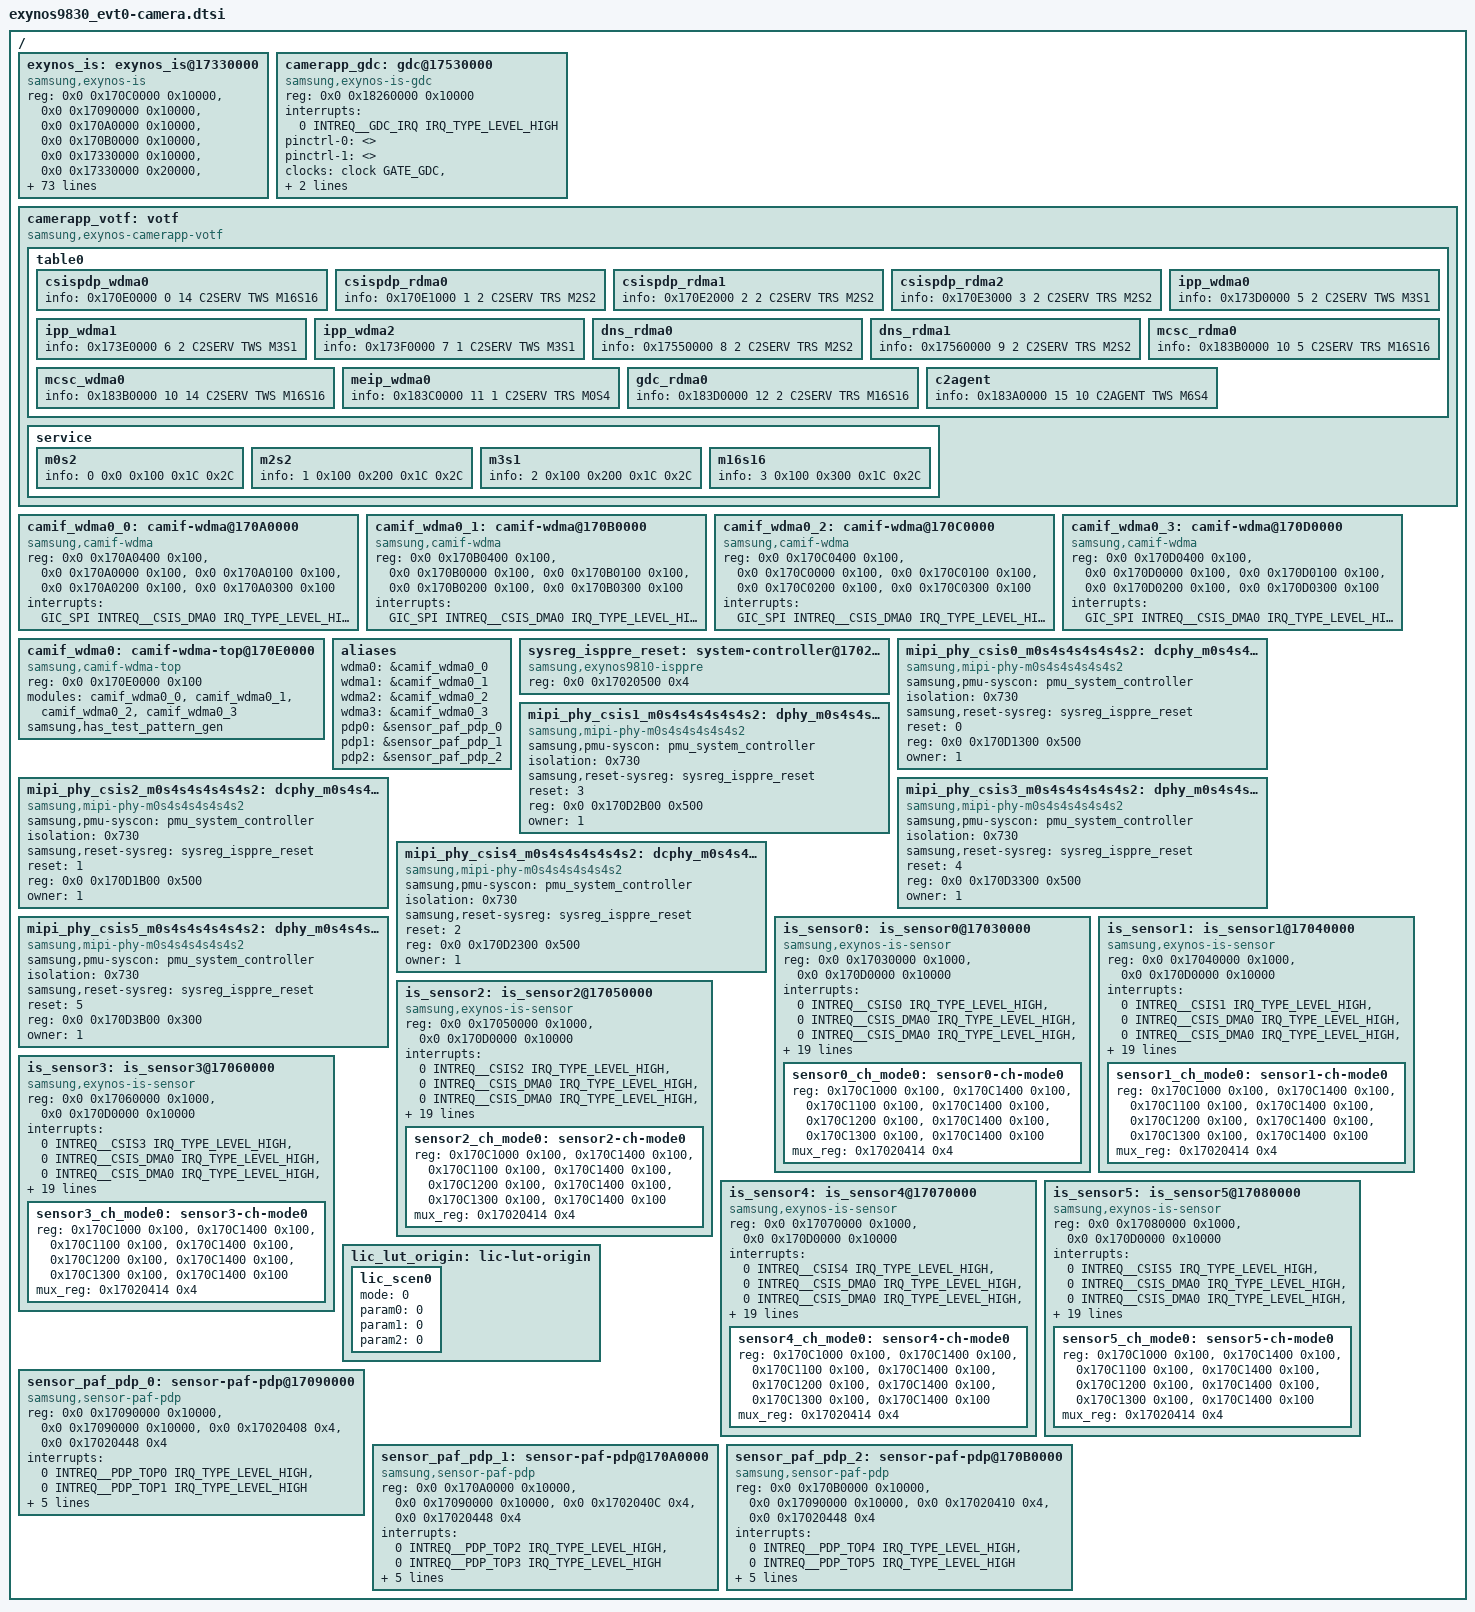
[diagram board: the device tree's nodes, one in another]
/*
 * SAMSUNG EXYNOS9830 SoC camera device tree source
 *
 * Copyright (c) 2019 Samsung Electronics Co., Ltd.
 *		http://www.samsung.com
 *
 * SAMSUNG EXYNOS9830 SoC camera device nodes are listed in this file.
 * EXYNOS9830 based board files can include this file and provide
 * values for board specfic bindings.
 *
 * This program is free software; you can redistribute it and/or modify
 * it under the terms of the GNU General Public License version 2 as
 * published by the Free Software Foundation.
 */

#include <dt-bindings/clock/exynos9830_evt0.h>
#include <dt-bindings/interrupt-controller/arm-gic.h>
#include <dt-bindings/interrupt-controller/exynos9830.h>
#include <dt-bindings/sysmmu/sysmmu.h>
#include <dt-bindings/camera/exynos_is_dt.h>
#include <dt-bindings/camera/votf.h>
#include "exynos9830-pinctrl.dtsi"

/ {
	exynos_is: exynos_is@17330000 {
		compatible = "samsung,exynos-is";
		reg = <0x0 0x170C0000 0x10000>, /* CSIS DMA  */
			<0x0 0x17090000 0x10000>, /* PDP CORE0 */
			<0x0 0x170A0000 0x10000>, /* PDP CORE1 */
			<0x0 0x170B0000 0x10000>, /* PDP CORE2 */
			<0x0 0x17330000 0x10000>, /* IPP0 */
			<0x0 0x17330000 0x20000>, /* IPP1 */
			<0x0 0x17330000 0x30000>, /* IPP2 */
			<0x0 0x170C0000 0x10000>, /* ZSL/STRIP DMA  */
			<0x0 0x18250000 0x10000>, /* MEIP */
			<0x0 0x17430000 0x10000>, /* ITP0 */
			<0x0 0x17740000 0x10000>, /* TNR */
			<0x0 0x17530000 0x10000>, /* DNS0 */
			<0x0 0x18240000 0x10000>, /* MCSC */
			<0x0 0x18230000 0x10000>, /* ITSC only for EVT0 */
			<0x0 0x17440000 0x10000>, /* ITP1 only for EVT0 */
			<0x0 0x17540000 0x10000>; /* DNS1 only for EVT0 */
		interrupts = <0 INTREQ__IPP_CH0_0 IRQ_TYPE_LEVEL_HIGH>,	/* IPP0_0 */
			<0 INTREQ__IPP_CH0_1 IRQ_TYPE_LEVEL_HIGH>,			/* IPP0_1 */
			<0 INTREQ__MEIP_0 IRQ_TYPE_LEVEL_HIGH>,				/* MEIP_0 */
			<0 INTREQ__ZSL_DMA0 IRQ_TYPE_LEVEL_HIGH>,				/* ZSL_DMA_0 */
			<0 INTREQ__STRP_DMA0 IRQ_TYPE_LEVEL_HIGH>,			/* STRIP_DMA_0 */
			<0 INTREQ__IPP_CH1_0 IRQ_TYPE_LEVEL_HIGH>,			/* IPP1_0 */
			<0 INTREQ__IPP_CH1_1 IRQ_TYPE_LEVEL_HIGH>,			/* IPP1_1 */
			<0 INTREQ__MEIP_1 IRQ_TYPE_LEVEL_HIGH>,				/* MEIP_1 */
			<0 INTREQ__ZSL_DMA1 IRQ_TYPE_LEVEL_HIGH>,				/* ZSL_DMA_1 */
			<0 INTREQ__STRP_DMA1 IRQ_TYPE_LEVEL_HIGH>,			/* STRIP_DMA_1 */
			<0 INTREQ__IPP_CH2_0 IRQ_TYPE_LEVEL_HIGH>,			/* IPP2_0 */
			<0 INTREQ__IPP_CH2_1 IRQ_TYPE_LEVEL_HIGH>,			/* IPP2_1 */
			<0 INTREQ__ZSL_DMA2 IRQ_TYPE_LEVEL_HIGH>,				/* ZSL_DMA_2 */
			<0 INTREQ__STRP_DMA2 IRQ_TYPE_LEVEL_HIGH>,			/* STRIP_DMA_2 */
			<0 INTREQ__DNS0_0 IRQ_TYPE_LEVEL_HIGH>,				/* ITP0_0 */
			<0 INTREQ__DNS0_1 IRQ_TYPE_LEVEL_HIGH>,				/* ITP0_1 */
			<0 INTREQ__TNR IRQ_TYPE_LEVEL_HIGH>,					/* TNR */
			<0 INTREQ__MCSC_OTF0 IRQ_TYPE_LEVEL_HIGH>,			/* MC_SC_0 */
			<0 INTREQ__MCSC_OTF1 IRQ_TYPE_LEVEL_HIGH>,			/* MC_SC_1 */
			<0 INTREQ__DNS1_0 IRQ_TYPE_LEVEL_HIGH>,				/* ITP1_0 */
			<0 INTREQ__DNS1_1 IRQ_TYPE_LEVEL_HIGH>,				/* ITP1_1 */
			<0 INTREQ__ITSC_OTF0 IRQ_TYPE_LEVEL_HIGH>,			/* ITSC_0 */
			<0 INTREQ__ITSC_OTF1 IRQ_TYPE_LEVEL_HIGH>;			/* ITSC_1 */
		pinctrl-names = "default","release";
		pinctrl-0 = <>;
		pinctrl-1 = <>;
		clocks = <&clock UMUX_CLKCMU_IPP_BUS>,
			<&clock GATE_SIPU_IPP>,

			<&clock UMUX_CLKCMU_TNR_BUS>,
			<&clock DOUT_CLK_TNR_BUSP>,
			<&clock GATE_TNR>,

			<&clock UMUX_CLKCMU_DNS_BUS>,
			<&clock GATE_DNS>,

			<&clock UMUX_CLKCMU_ITP_BUS>,
			<&clock GATE_ITP>,

			<&clock UMUX_CLKCMU_MCSC_BUS>,
			<&clock UMUX_CLKCMU_MCSC_MEIP>,
			<&clock UMUX_CLKCMU_MCSC_GDC>,
			<&clock GATE_GDC>,
			<&clock GATE_ITSC>,
			<&clock GATE_MCSC>,
			<&clock GATE_MEIP>,

			<&clock CIS_CLK0>,
			<&clock CIS_CLK1>,
			<&clock CIS_CLK2>,
			<&clock CIS_CLK3>,
			<&clock CIS_CLK4>,
			<&clock CIS_CLK5>,

			<&clock GATE_DFTMUX_TOP_CIS_CLK0>,
			<&clock GATE_DFTMUX_TOP_CIS_CLK1>,
			<&clock GATE_DFTMUX_TOP_CIS_CLK2>,
			<&clock GATE_DFTMUX_TOP_CIS_CLK3>,
			<&clock GATE_DFTMUX_TOP_CIS_CLK4>,
			<&clock GATE_DFTMUX_TOP_CIS_CLK5>,

			<&clock UMUX_CLKCMU_CSIS_BUS>,
			<&clock GATE_CSIS_PDP_CSIS0>,
			<&clock GATE_CSIS_PDP_CSIS1>,
			<&clock GATE_CSIS_PDP_CSIS2>,
			<&clock GATE_CSIS_PDP_CSIS3>,
			<&clock GATE_CSIS_PDP_CSIS4>,
			<&clock GATE_CSIS_PDP_CSIS_DMA>,
			<&clock GATE_CSIS_PDP_CSIS5>,
			<&clock GATE_CSIS_PDP_TOP>;
		clock-names = "UMUX_CLKCMU_IPP_BUS",
			"GATE_SIPU_IPP",

			"UMUX_CLKCMU_TNR_BUS",
			"DOUT_CLK_TNR_BUSP",
			"GATE_TNR",

			"UMUX_CLKCMU_DNS_BUS",
			"GATE_DNS",

			"UMUX_CLKCMU_ITP_BUS",
			"GATE_ITP",

			"UMUX_CLKCMU_MCSC_BUS",
			"UMUX_CLKCMU_MCSC_MEIP",
			"UMUX_CLKCMU_MCSC_GDC",
			"GATE_GDC",
			"GATE_ITSC",
			"GATE_MCSC",
			"GATE_MEIP",

			"CIS_CLK0",
			"CIS_CLK1",
			"CIS_CLK2",
			"CIS_CLK3",
			"CIS_CLK4",
			"CIS_CLK5",

			"MUX_CIS_CLK0",
			"MUX_CIS_CLK1",
			"MUX_CIS_CLK2",
			"MUX_CIS_CLK3",
			"MUX_CIS_CLK4",
			"MUX_CIS_CLK5",

			"UMUX_CLKCMU_CSIS_BUS",
			"GATE_CSIS_PDP_CSIS0",
			"GATE_CSIS_PDP_CSIS1",
			"GATE_CSIS_PDP_CSIS2",
			"GATE_CSIS_PDP_CSIS3",
			"GATE_CSIS_PDP_CSIS4",
			"GATE_CSIS_PDP_CSIS_DMA",
			"GATE_CSIS_PDP_CSIS5",
			"GATE_CSIS_PDP_TOP";
		status = "ok";
		iommus = <&sysmmu_csis1>, <&sysmmu_ipp>, <&sysmmu_tnr>, <&sysmmu_dns>, <&sysmmu_mcsc0>, <&sysmmu_mcsc1>;
		#cooling-cells = <2>; /* min followed by max */
		/* ewf-index = <EWF_CMU_BUSC>; */
		list-scen-bts = "camera_default";
		num_of_3aa = <3>;
		num_of_isp = <1>;
		num_of_mcsc = <1>;
		num_of_vra = <0>;
		num_of_clh = <0>;
	};

	camerapp_gdc: gdc@17530000 {
		compatible = "samsung,exynos-is-gdc";
		reg = <0x0 0x18260000 0x10000>; /* GDC */
		interrupts = <0 INTREQ__GDC_IRQ IRQ_TYPE_LEVEL_HIGH>; /* GDC */
		pinctrl-names = "default","release";
		pinctrl-0 = <>;
		pinctrl-1 = <>;
		clocks = <&clock GATE_GDC>,
			<&clock UMUX_CLKCMU_MCSC_GDC>;
		clock-names = "gate",
			"gate2";
		status = "okay";
		iommus = <&sysmmu_mcsc0>;
		#cooling-cells = <2>; /* min followed by max */
	};

	camerapp_votf: votf {
		compatible = "samsung,exynos-camerapp-votf";
		status = "okay";

		table0{
			/* base address, ip num, id cnt, C2SERV/C2AGENT, TWS/TRS, module type */
			csispdp_wdma0 {	info = <0x170E0000 0 14 C2SERV TWS M16S16>; };
			csispdp_rdma0 { info = <0x170E1000 1 2 C2SERV TRS M2S2>; };
			csispdp_rdma1 { info = <0x170E2000 2 2 C2SERV TRS M2S2>; };
			csispdp_rdma2 { info = <0x170E3000 3 2 C2SERV TRS M2S2>; };

			ipp_wdma0 { info= <0x173D0000 5 2 C2SERV TWS M3S1>; };
			ipp_wdma1 { info = <0x173E0000 6 2 C2SERV TWS M3S1>; };
			ipp_wdma2 { info = <0x173F0000 7 1 C2SERV TWS M3S1>; };

			dns_rdma0 { info = <0x17550000 8 2 C2SERV TRS M2S2>; };
			dns_rdma1 { info = <0x17560000 9 2 C2SERV TRS M2S2>; };

			mcsc_wdma0 { info = <0x183B0000 10 14 C2SERV TWS M16S16>; };
			mcsc_rdma0 { info = <0x183B0000 10 5 C2SERV TRS M16S16>; };

			meip_wdma0 { info = <0x183C0000 11 1 C2SERV TRS M0S4>; };
			gdc_rdma0 { info = <0x183D0000 12 2 C2SERV TRS M16S16>; };

			c2agent { info = < 0x183A0000 15 10 C2AGENT TWS M6S4>; };
		};

		service {
			/* num, tws addr, trs addr, tws gap, trs gap */
			m0s2 { info = <0 0x0 0x100 0x1C 0x2C>; };
			m2s2 { info = <1 0x100 0x200 0x1C 0x2C>; };
			m3s1 { info = <2 0x100 0x200 0x1C 0x2C>; };
			m16s16 { info = <3 0x100 0x300 0x1C 0x2C>; };
		};
	};

	camif_wdma0_0: camif-wdma@170A0000 {
		compatible = "samsung,camif-wdma";
		reg = <0x0 0x170A0400 0x100>, /* Common */
			<0x0 0x170A0000 0x100>, /* VC0 */
			<0x0 0x170A0100 0x100>, /* VC1 */
			<0x0 0x170A0200 0x100>, /* VC2 */
			<0x0 0x170A0300 0x100>; /* VC3 */
		reg-names = "common", "ch0", "ch1", "ch2", "ch3";
		interrupts = <GIC_SPI INTREQ__CSIS_DMA0 IRQ_TYPE_LEVEL_HIGH>;
	};

	camif_wdma0_1: camif-wdma@170B0000 {
		compatible = "samsung,camif-wdma";
		reg = <0x0 0x170B0400 0x100>, /* Common */
			<0x0 0x170B0000 0x100>, /* VC0 */
			<0x0 0x170B0100 0x100>, /* VC1 */
			<0x0 0x170B0200 0x100>, /* VC2 */
			<0x0 0x170B0300 0x100>; /* VC3 */
		reg-names = "common", "ch0", "ch1", "ch2", "ch3";
		interrupts = <GIC_SPI INTREQ__CSIS_DMA0 IRQ_TYPE_LEVEL_HIGH>;
	};

	camif_wdma0_2: camif-wdma@170C0000 {
		compatible = "samsung,camif-wdma";
		reg = <0x0 0x170C0400 0x100>, /* Common */
			<0x0 0x170C0000 0x100>, /* VC0 */
			<0x0 0x170C0100 0x100>, /* VC1 */
			<0x0 0x170C0200 0x100>, /* VC2 */
			<0x0 0x170C0300 0x100>; /* VC3 */
		reg-names = "common", "ch0", "ch1", "ch2", "ch3";
		interrupts = <GIC_SPI INTREQ__CSIS_DMA0 IRQ_TYPE_LEVEL_HIGH>;
	};

	camif_wdma0_3: camif-wdma@170D0000 {
		compatible = "samsung,camif-wdma";
		reg = <0x0 0x170D0400 0x100>, /* Common */
			<0x0 0x170D0000 0x100>, /* VC0 */
			<0x0 0x170D0100 0x100>, /* VC1 */
			<0x0 0x170D0200 0x100>, /* VC2 */
			<0x0 0x170D0300 0x100>; /* VC3 */
		reg-names = "common", "ch0", "ch1", "ch2", "ch3";
		interrupts = <GIC_SPI INTREQ__CSIS_DMA0 IRQ_TYPE_LEVEL_HIGH>;
	};

	camif_wdma0: camif-wdma-top@170E0000 {
		compatible = "samsung,camif-wdma-top";
		reg = <0x0 0x170E0000 0x100>;
		modules = <&camif_wdma0_0>,
			<&camif_wdma0_1>,
			<&camif_wdma0_2>,
			<&camif_wdma0_3>;
		samsung,has_test_pattern_gen;
	};

	aliases {
		wdma0 = &camif_wdma0_0;
		wdma1 = &camif_wdma0_1;
		wdma2 = &camif_wdma0_2;
		wdma3 = &camif_wdma0_3;
	};

	sysreg_isppre_reset: system-controller@17020500 {
		compatible = "samsung,exynos9810-isppre", "syscon";
		reg = <0x0 0x17020500 0x4>;
	};

	mipi_phy_csis0_m0s4s4s4s4s4s2: dcphy_m0s4s4s4s4s4s2_csi0@17020500 {
		/* DPHY 6.5 Gbps 4lane */
		/* CPHY 3.5 Gbps 3lane */
		compatible = "samsung,mipi-phy-m0s4s4s4s4s4s2";
		samsung,pmu-syscon = <&pmu_system_controller>;
		isolation = <0x730>; /* PMU address offset */
		samsung,reset-sysreg = <&sysreg_isppre_reset>;
		reset = <0>; /* reset bit */
		reg = <0x0 0x170D1300 0x500>;
		owner = <1>; /* 0: DSI,  1: CSI */
		#phy-cells = <1>;
	};

	mipi_phy_csis1_m0s4s4s4s4s4s2: dphy_m0s4s4s4s4s4s2_csi1@17020500 {
		/* DPHY 6.5 Gbps 4lane */
		compatible = "samsung,mipi-phy-m0s4s4s4s4s4s2";
		samsung,pmu-syscon = <&pmu_system_controller>;
		isolation = <0x730>; /* PMU address offset */
		samsung,reset-sysreg = <&sysreg_isppre_reset>;
		reset = <3>; /* reset bit */
		reg = <0x0 0x170D2B00 0x500>;
		owner = <1>; /* 0: DSI,  1: CSI */
		#phy-cells = <1>;
	};

	mipi_phy_csis2_m0s4s4s4s4s4s2: dcphy_m0s4s4s4s4s4s2_csi2@17020500 {
		/* DPHY 6.5 Gbps 4lane */
		/* CPHY 3.5 Gbps 3lane */
		compatible = "samsung,mipi-phy-m0s4s4s4s4s4s2";
		samsung,pmu-syscon = <&pmu_system_controller>;
		isolation = <0x730>; /* PMU address offset */
		samsung,reset-sysreg = <&sysreg_isppre_reset>;
		reset = <1>; /* reset bit */
		reg = <0x0 0x170D1B00 0x500>;
		owner = <1>; /* 0: DSI,  1: CSI */
		#phy-cells = <1>;
	};

	mipi_phy_csis3_m0s4s4s4s4s4s2: dphy_m0s4s4s4s4s4s2_csi3@17020500 {
		/* DPHY 6.5 Gbps 4lane */
		compatible = "samsung,mipi-phy-m0s4s4s4s4s4s2";
		samsung,pmu-syscon = <&pmu_system_controller>;
		isolation = <0x730>; /* PMU address offset */
		samsung,reset-sysreg = <&sysreg_isppre_reset>;
		reset = <4>; /* reset bit */
		reg = <0x0 0x170D3300 0x500>;
		owner = <1>; /* 0: DSI,  1: CSI */
		#phy-cells = <1>;
	};

	mipi_phy_csis4_m0s4s4s4s4s4s2: dcphy_m0s4s4s4s4s4s2_csi4@17020500 {
		/* DPHY 6.5 Gbps 4lane */
		/* CPHY 3.5 Gbps 3lane */
		compatible = "samsung,mipi-phy-m0s4s4s4s4s4s2";
		samsung,pmu-syscon = <&pmu_system_controller>;
		isolation = <0x730>; /* PMU address offset */
		samsung,reset-sysreg = <&sysreg_isppre_reset>;
		reset = <2>; /* reset bit */
		reg = <0x0 0x170D2300 0x500>;
		owner = <1>; /* 0: DSI,  1: CSI */
		#phy-cells = <1>;
	};

	mipi_phy_csis5_m0s4s4s4s4s4s2: dphy_m0s4s4s4s4s4s2_csi5@17020500 {
		/* DPHY 6.5 Gbps 2lane */
		compatible = "samsung,mipi-phy-m0s4s4s4s4s4s2";
		samsung,pmu-syscon = <&pmu_system_controller>;
		isolation = <0x730>; /* PMU address offset */
		samsung,reset-sysreg = <&sysreg_isppre_reset>;
		reset = <5>; /* reset bit */
		reg = <0x0 0x170D3B00 0x300>;
		owner = <1>; /* 0: DSI,  1: CSI */
		#phy-cells = <1>;
	};

	is_sensor0: is_sensor0@17030000 {
		/* CSIS0 */
		compatible = "samsung,exynos-is-sensor";
		#address-cells = <1>;
		#size-cells = <1>;
		reg = <0x0 0x17030000 0x1000>, /* MIPI-CSI0 */
			<0x0 0x170D0000 0x10000>; /* PHY: M0S4S4S4S4S4S2 */
		reg-names = "csi", "phy";
		interrupts = <0 INTREQ__CSIS0 IRQ_TYPE_LEVEL_HIGH>, /*MIPI-CSI0 */
			<0 INTREQ__CSIS_DMA0 IRQ_TYPE_LEVEL_HIGH>,
			<0 INTREQ__CSIS_DMA0 IRQ_TYPE_LEVEL_HIGH>,
			<0 INTREQ__CSIS_DMA0 IRQ_TYPE_LEVEL_HIGH>,
			<0 INTREQ__CSIS_DMA0 IRQ_TYPE_LEVEL_HIGH>;
		interrupt-names = "csi",
			"mode0_VC0", "mode0_VC1","mode0_VC2","mode0_VC3";
		phys = <&mipi_phy_csis0_m0s4s4s4s4s4s2 0>;
		phy-names = "csis_dphy";
		clocks = <&clock CIS_CLK0>,
			<&clock CIS_CLK1>,
			<&clock CIS_CLK2>,
			<&clock CIS_CLK3>,
			<&clock CIS_CLK4>,
			<&clock CIS_CLK5>,

			<&clock GATE_DFTMUX_TOP_CIS_CLK0>,
			<&clock GATE_DFTMUX_TOP_CIS_CLK1>,
			<&clock GATE_DFTMUX_TOP_CIS_CLK2>,
			<&clock GATE_DFTMUX_TOP_CIS_CLK3>,
			<&clock GATE_DFTMUX_TOP_CIS_CLK4>,
			<&clock GATE_DFTMUX_TOP_CIS_CLK5>,

			<&clock GATE_CSIS_PDP_CSIS0>,
			<&clock GATE_CSIS_PDP_CSIS1>,
			<&clock GATE_CSIS_PDP_CSIS2>,
			<&clock GATE_CSIS_PDP_CSIS3>,
			<&clock GATE_CSIS_PDP_CSIS4>,
			<&clock GATE_CSIS_PDP_CSIS5>;
		clock-names = "CIS_CLK0",
			"CIS_CLK1",
			"CIS_CLK2",
			"CIS_CLK3",
			"CIS_CLK4",
			"CIS_CLK5",

			"MUX_CIS_CLK0",
			"MUX_CIS_CLK1",
			"MUX_CIS_CLK2",
			"MUX_CIS_CLK3",
			"MUX_CIS_CLK4",
			"MUX_CIS_CLK5",

			"GATE_CSIS_PDP_CSIS0",
			"GATE_CSIS_PDP_CSIS1",
			"GATE_CSIS_PDP_CSIS2",
			"GATE_CSIS_PDP_CSIS3",
			"GATE_CSIS_PDP_CSIS4",
			"GATE_CSIS_PDP_CSIS5";
		iommus = <&sysmmu_csis0>, <&sysmmu_csis1>;

		/* without PAF HW */
		sensor0_ch_mode0: sensor0-ch-mode0 {
			reg = <0x170C1000 0x100>, /* DMA0 VC0 */
				<0x170C1400 0x100>, /* DMA0 Common */
				<0x170C1100 0x100>, /* DMA0 VC1 */
				<0x170C1400 0x100>, /* DMA0 Common */
				<0x170C1200 0x100>, /* DMA0 VC2 */
				<0x170C1400 0x100>, /* DMA0 Common */
				<0x170C1300 0x100>, /* DMA0 VC3 */
				<0x170C1400 0x100>; /* DMA0 Common */
			mux_reg = <0x17020414 0x4>; /* DMA0 input mux */
		};
	};

	is_sensor1: is_sensor1@17040000 {
		/* CSIS1 */
		compatible = "samsung,exynos-is-sensor";
		#address-cells = <1>;
		#size-cells = <1>;
		reg = <0x0 0x17040000 0x1000>, /* MIPI-CSI1 */
			<0x0 0x170D0000 0x10000>; /* PHY: M0S4S4S4S4S4S2 */
		reg-names = "csi", "phy";
		interrupts = <0 INTREQ__CSIS1 IRQ_TYPE_LEVEL_HIGH>, /* MIPI-CSI1 */
			<0 INTREQ__CSIS_DMA0 IRQ_TYPE_LEVEL_HIGH>,
			<0 INTREQ__CSIS_DMA0 IRQ_TYPE_LEVEL_HIGH>,
			<0 INTREQ__CSIS_DMA0 IRQ_TYPE_LEVEL_HIGH>,
			<0 INTREQ__CSIS_DMA0 IRQ_TYPE_LEVEL_HIGH>;
		interrupt-names = "csi",
			"mode0_VC0", "mode0_VC1","mode0_VC2","mode0_VC3";
		phys = <&mipi_phy_csis1_m0s4s4s4s4s4s2 0>;
		phy-names = "csis_dphy";
		clocks = <&clock CIS_CLK0>,
			<&clock CIS_CLK1>,
			<&clock CIS_CLK2>,
			<&clock CIS_CLK3>,
			<&clock CIS_CLK4>,
			<&clock CIS_CLK5>,

			<&clock GATE_DFTMUX_TOP_CIS_CLK0>,
			<&clock GATE_DFTMUX_TOP_CIS_CLK1>,
			<&clock GATE_DFTMUX_TOP_CIS_CLK2>,
			<&clock GATE_DFTMUX_TOP_CIS_CLK3>,
			<&clock GATE_DFTMUX_TOP_CIS_CLK4>,
			<&clock GATE_DFTMUX_TOP_CIS_CLK5>,

			<&clock GATE_CSIS_PDP_CSIS0>,
			<&clock GATE_CSIS_PDP_CSIS1>,
			<&clock GATE_CSIS_PDP_CSIS2>,
			<&clock GATE_CSIS_PDP_CSIS3>,
			<&clock GATE_CSIS_PDP_CSIS4>,
			<&clock GATE_CSIS_PDP_CSIS5>;
		clock-names = "CIS_CLK0",
			"CIS_CLK1",
			"CIS_CLK2",
			"CIS_CLK3",
			"CIS_CLK4",
			"CIS_CLK5",

			"MUX_CIS_CLK0",
			"MUX_CIS_CLK1",
			"MUX_CIS_CLK2",
			"MUX_CIS_CLK3",
			"MUX_CIS_CLK4",
			"MUX_CIS_CLK5",

			"GATE_CSIS_PDP_CSIS0",
			"GATE_CSIS_PDP_CSIS1",
			"GATE_CSIS_PDP_CSIS2",
			"GATE_CSIS_PDP_CSIS3",
			"GATE_CSIS_PDP_CSIS4",
			"GATE_CSIS_PDP_CSIS5";
		iommus = <&sysmmu_csis0>, <&sysmmu_csis1>;

		/* without PAF HW */
		sensor1_ch_mode0: sensor1-ch-mode0 {
			reg = <0x170C1000 0x100>, /* DMA0 VC0 */
				<0x170C1400 0x100>, /* DMA0 Common */
				<0x170C1100 0x100>, /* DMA0 VC1 */
				<0x170C1400 0x100>, /* DMA0 Common */
				<0x170C1200 0x100>, /* DMA0 VC2 */
				<0x170C1400 0x100>, /* DMA0 Common */
				<0x170C1300 0x100>, /* DMA0 VC3 */
				<0x170C1400 0x100>; /* DMA0 Common */
			mux_reg = <0x17020414 0x4>; /* DMA0 input mux */
		};
	};

	is_sensor2: is_sensor2@17050000 {
		/* CSIS2 */
		compatible = "samsung,exynos-is-sensor";
		#address-cells = <1>;
		#size-cells = <1>;
		reg = <0x0 0x17050000 0x1000>, /* MIPI-CSI2 */
			<0x0 0x170D0000 0x10000>; /* PHY: M0S4S4S4S4S4S2 */
		reg-names = "csi", "phy";
		interrupts = <0 INTREQ__CSIS2 IRQ_TYPE_LEVEL_HIGH>, /* MIPI-CSI2 */
			<0 INTREQ__CSIS_DMA0 IRQ_TYPE_LEVEL_HIGH>,
			<0 INTREQ__CSIS_DMA0 IRQ_TYPE_LEVEL_HIGH>,
			<0 INTREQ__CSIS_DMA0 IRQ_TYPE_LEVEL_HIGH>,
			<0 INTREQ__CSIS_DMA0 IRQ_TYPE_LEVEL_HIGH>;
		interrupt-names = "csi",
			"mode0_VC0", "mode0_VC1","mode0_VC2","mode0_VC3";
		phys = <&mipi_phy_csis2_m0s4s4s4s4s4s2 0>;
		phy-names = "csis_dphy";
		clocks = <&clock CIS_CLK0>,
			<&clock CIS_CLK1>,
			<&clock CIS_CLK2>,
			<&clock CIS_CLK3>,
			<&clock CIS_CLK4>,
			<&clock CIS_CLK5>,

			<&clock GATE_DFTMUX_TOP_CIS_CLK0>,
			<&clock GATE_DFTMUX_TOP_CIS_CLK1>,
			<&clock GATE_DFTMUX_TOP_CIS_CLK2>,
			<&clock GATE_DFTMUX_TOP_CIS_CLK3>,
			<&clock GATE_DFTMUX_TOP_CIS_CLK4>,
			<&clock GATE_DFTMUX_TOP_CIS_CLK5>,

			<&clock GATE_CSIS_PDP_CSIS0>,
			<&clock GATE_CSIS_PDP_CSIS1>,
			<&clock GATE_CSIS_PDP_CSIS2>,
			<&clock GATE_CSIS_PDP_CSIS3>,
			<&clock GATE_CSIS_PDP_CSIS4>,
			<&clock GATE_CSIS_PDP_CSIS5>;
		clock-names = "CIS_CLK0",
			"CIS_CLK1",
			"CIS_CLK2",
			"CIS_CLK3",
			"CIS_CLK4",
			"CIS_CLK5",

			"MUX_CIS_CLK0",
			"MUX_CIS_CLK1",
			"MUX_CIS_CLK2",
			"MUX_CIS_CLK3",
			"MUX_CIS_CLK4",
			"MUX_CIS_CLK5",

			"GATE_CSIS_PDP_CSIS0",
			"GATE_CSIS_PDP_CSIS1",
			"GATE_CSIS_PDP_CSIS2",
			"GATE_CSIS_PDP_CSIS3",
			"GATE_CSIS_PDP_CSIS4",
			"GATE_CSIS_PDP_CSIS5";
		iommus = <&sysmmu_csis0>, <&sysmmu_csis1>;

		/* without PAF HW */
		sensor2_ch_mode0: sensor2-ch-mode0 {
			reg = <0x170C1000 0x100>, /* DMA0 VC0 */
				<0x170C1400 0x100>, /* DMA0 Common */
				<0x170C1100 0x100>, /* DMA0 VC1 */
				<0x170C1400 0x100>, /* DMA0 Common */
				<0x170C1200 0x100>, /* DMA0 VC2 */
				<0x170C1400 0x100>, /* DMA0 Common */
				<0x170C1300 0x100>, /* DMA0 VC3 */
				<0x170C1400 0x100>; /* DMA0 Common */
			mux_reg = <0x17020414 0x4>; /* DMA0 input mux */
		};
	};

	is_sensor3: is_sensor3@17060000 {
		/* CSIS3 */
		compatible = "samsung,exynos-is-sensor";
		#address-cells = <1>;
		#size-cells = <1>;
		#interrupt-cells = <1>;
		reg = <0x0 0x17060000 0x1000>, /* MIPI-CSI3 */
			<0x0 0x170D0000 0x10000>; /* PHY: M0S4S4S4S4S4S2 */
		reg-names = "csi", "phy";
		interrupts = <0 INTREQ__CSIS3 IRQ_TYPE_LEVEL_HIGH>, /* MIPI-CSI3 */
			<0 INTREQ__CSIS_DMA0 IRQ_TYPE_LEVEL_HIGH>,
			<0 INTREQ__CSIS_DMA0 IRQ_TYPE_LEVEL_HIGH>,
			<0 INTREQ__CSIS_DMA0 IRQ_TYPE_LEVEL_HIGH>,
			<0 INTREQ__CSIS_DMA0 IRQ_TYPE_LEVEL_HIGH>;
		interrupt-names = "csi",
			"mode0_VC0", "mode0_VC1","mode0_VC2","mode0_VC3";
		phys = <&mipi_phy_csis3_m0s4s4s4s4s4s2 0>;
		phy-names = "csis_dphy";
		clocks = <&clock CIS_CLK0>,
			<&clock CIS_CLK1>,
			<&clock CIS_CLK2>,
			<&clock CIS_CLK3>,
			<&clock CIS_CLK4>,
			<&clock CIS_CLK5>,

			<&clock GATE_DFTMUX_TOP_CIS_CLK0>,
			<&clock GATE_DFTMUX_TOP_CIS_CLK1>,
			<&clock GATE_DFTMUX_TOP_CIS_CLK2>,
			<&clock GATE_DFTMUX_TOP_CIS_CLK3>,
			<&clock GATE_DFTMUX_TOP_CIS_CLK4>,
			<&clock GATE_DFTMUX_TOP_CIS_CLK5>,

			<&clock GATE_CSIS_PDP_CSIS0>,
			<&clock GATE_CSIS_PDP_CSIS1>,
			<&clock GATE_CSIS_PDP_CSIS2>,
			<&clock GATE_CSIS_PDP_CSIS3>,
			<&clock GATE_CSIS_PDP_CSIS4>,
			<&clock GATE_CSIS_PDP_CSIS5>;
		clock-names = "CIS_CLK0",
			"CIS_CLK1",
			"CIS_CLK2",
			"CIS_CLK3",
			"CIS_CLK4",
			"CIS_CLK5",

			"MUX_CIS_CLK0",
			"MUX_CIS_CLK1",
			"MUX_CIS_CLK2",
			"MUX_CIS_CLK3",
			"MUX_CIS_CLK4",
			"MUX_CIS_CLK5",

			"GATE_CSIS_PDP_CSIS0",
			"GATE_CSIS_PDP_CSIS1",
			"GATE_CSIS_PDP_CSIS2",
			"GATE_CSIS_PDP_CSIS3",
			"GATE_CSIS_PDP_CSIS4",
			"GATE_CSIS_PDP_CSIS5";
		iommus = <&sysmmu_csis0>, <&sysmmu_csis1>;

		/* without PAF HW */
		sensor3_ch_mode0: sensor3-ch-mode0 {
			reg = <0x170C1000 0x100>, /* DMA0 VC0 */
				<0x170C1400 0x100>, /* DMA0 Common */
				<0x170C1100 0x100>, /* DMA0 VC1 */
				<0x170C1400 0x100>, /* DMA0 Common */
				<0x170C1200 0x100>, /* DMA0 VC2 */
				<0x170C1400 0x100>, /* DMA0 Common */
				<0x170C1300 0x100>, /* DMA0 VC3 */
				<0x170C1400 0x100>; /* DMA0 Common */
			mux_reg = <0x17020414 0x4>; /* DMA0 input mux */
		};
	};

	is_sensor4: is_sensor4@17070000 {
		/* CSIS4 */
		compatible = "samsung,exynos-is-sensor";
		#address-cells = <1>;
		#size-cells = <1>;
		reg = <0x0 0x17070000 0x1000>, /* MIPI-CSI4 */
			<0x0 0x170D0000 0x10000>; /* PHY: M0S4S4S4S4S4S2 */
		reg-names = "csi", "phy";
		interrupts = <0 INTREQ__CSIS4 IRQ_TYPE_LEVEL_HIGH>, /* MIPI-CSI4 */
			<0 INTREQ__CSIS_DMA0 IRQ_TYPE_LEVEL_HIGH>,
			<0 INTREQ__CSIS_DMA0 IRQ_TYPE_LEVEL_HIGH>,
			<0 INTREQ__CSIS_DMA0 IRQ_TYPE_LEVEL_HIGH>,
			<0 INTREQ__CSIS_DMA0 IRQ_TYPE_LEVEL_HIGH>;
		interrupt-names = "csi",
			"mode0_VC0", "mode0_VC1","mode0_VC2","mode0_VC3";
		phys = <&mipi_phy_csis4_m0s4s4s4s4s4s2 0>;
		phy-names = "csis_dphy";
		clocks = <&clock CIS_CLK0>,
			<&clock CIS_CLK1>,
			<&clock CIS_CLK2>,
			<&clock CIS_CLK3>,
			<&clock CIS_CLK4>,
			<&clock CIS_CLK5>,

			<&clock GATE_DFTMUX_TOP_CIS_CLK0>,
			<&clock GATE_DFTMUX_TOP_CIS_CLK1>,
			<&clock GATE_DFTMUX_TOP_CIS_CLK2>,
			<&clock GATE_DFTMUX_TOP_CIS_CLK3>,
			<&clock GATE_DFTMUX_TOP_CIS_CLK4>,
			<&clock GATE_DFTMUX_TOP_CIS_CLK5>,

			<&clock GATE_CSIS_PDP_CSIS0>,
			<&clock GATE_CSIS_PDP_CSIS1>,
			<&clock GATE_CSIS_PDP_CSIS2>,
			<&clock GATE_CSIS_PDP_CSIS3>,
			<&clock GATE_CSIS_PDP_CSIS4>,
			<&clock GATE_CSIS_PDP_CSIS5>;
		clock-names = "CIS_CLK0",
			"CIS_CLK1",
			"CIS_CLK2",
			"CIS_CLK3",
			"CIS_CLK4",
			"CIS_CLK5",

			"MUX_CIS_CLK0",
			"MUX_CIS_CLK1",
			"MUX_CIS_CLK2",
			"MUX_CIS_CLK3",
			"MUX_CIS_CLK4",
			"MUX_CIS_CLK5",

			"GATE_CSIS_PDP_CSIS0",
			"GATE_CSIS_PDP_CSIS1",
			"GATE_CSIS_PDP_CSIS2",
			"GATE_CSIS_PDP_CSIS3",
			"GATE_CSIS_PDP_CSIS4",
			"GATE_CSIS_PDP_CSIS5";
		iommus = <&sysmmu_csis0>, <&sysmmu_csis1>;

		/* without PAF HW */
		sensor4_ch_mode0: sensor4-ch-mode0 {
			reg = <0x170C1000 0x100>, /* DMA0 VC0 */
				<0x170C1400 0x100>, /* DMA0 Common */
				<0x170C1100 0x100>, /* DMA0 VC1 */
				<0x170C1400 0x100>, /* DMA0 Common */
				<0x170C1200 0x100>, /* DMA0 VC2 */
				<0x170C1400 0x100>, /* DMA0 Common */
				<0x170C1300 0x100>, /* DMA0 VC3 */
				<0x170C1400 0x100>; /* DMA0 Common */
			mux_reg = <0x17020414 0x4>; /* DMA0 input mux */
		};
	};

	is_sensor5: is_sensor5@17080000 {
		/* CSIS5 */
		compatible = "samsung,exynos-is-sensor";
		#address-cells = <1>;
		#size-cells = <1>;
		reg = <0x0 0x17080000 0x1000>, /* MIPI-CSI5 */
			<0x0 0x170D0000 0x10000>; /* PHY: M0S4S4S4S4S4S2 */
		reg-names = "csi", "phy";
		interrupts = <0 INTREQ__CSIS5 IRQ_TYPE_LEVEL_HIGH>, /* MIPI-CSI5 */
			<0 INTREQ__CSIS_DMA0 IRQ_TYPE_LEVEL_HIGH>,
			<0 INTREQ__CSIS_DMA0 IRQ_TYPE_LEVEL_HIGH>,
			<0 INTREQ__CSIS_DMA0 IRQ_TYPE_LEVEL_HIGH>,
			<0 INTREQ__CSIS_DMA0 IRQ_TYPE_LEVEL_HIGH>;
		interrupt-names = "csi",
			"mode0_VC0", "mode0_VC1","mode0_VC2","mode0_VC3";
		phys = <&mipi_phy_csis5_m0s4s4s4s4s4s2 0>;
		phy-names = "csis_dphy";
		clocks = <&clock CIS_CLK0>,
			<&clock CIS_CLK1>,
			<&clock CIS_CLK2>,
			<&clock CIS_CLK3>,
			<&clock CIS_CLK4>,
			<&clock CIS_CLK5>,

			<&clock GATE_DFTMUX_TOP_CIS_CLK0>,
			<&clock GATE_DFTMUX_TOP_CIS_CLK1>,
			<&clock GATE_DFTMUX_TOP_CIS_CLK2>,
			<&clock GATE_DFTMUX_TOP_CIS_CLK3>,
			<&clock GATE_DFTMUX_TOP_CIS_CLK4>,
			<&clock GATE_DFTMUX_TOP_CIS_CLK5>,

			<&clock GATE_CSIS_PDP_CSIS0>,
			<&clock GATE_CSIS_PDP_CSIS1>,
			<&clock GATE_CSIS_PDP_CSIS2>,
			<&clock GATE_CSIS_PDP_CSIS3>,
			<&clock GATE_CSIS_PDP_CSIS4>,
			<&clock GATE_CSIS_PDP_CSIS5>;
		clock-names = "CIS_CLK0",
			"CIS_CLK1",
			"CIS_CLK2",
			"CIS_CLK3",
			"CIS_CLK4",
			"CIS_CLK5",

			"MUX_CIS_CLK0",
			"MUX_CIS_CLK1",
			"MUX_CIS_CLK2",
			"MUX_CIS_CLK3",
			"MUX_CIS_CLK4",
			"MUX_CIS_CLK5",

			"GATE_CSIS_PDP_CSIS0",
			"GATE_CSIS_PDP_CSIS1",
			"GATE_CSIS_PDP_CSIS2",
			"GATE_CSIS_PDP_CSIS3",
			"GATE_CSIS_PDP_CSIS4",
			"GATE_CSIS_PDP_CSIS5";
		iommus = <&sysmmu_csis0>, <&sysmmu_csis1>;

		/* without PAF HW */
		sensor5_ch_mode0: sensor5-ch-mode0 {
			reg = <0x170C1000 0x100>, /* DMA0 VC0 */
				<0x170C1400 0x100>, /* DMA0 Common */
				<0x170C1100 0x100>, /* DMA0 VC1 */
				<0x170C1400 0x100>, /* DMA0 Common */
				<0x170C1200 0x100>, /* DMA0 VC2 */
				<0x170C1400 0x100>, /* DMA0 Common */
				<0x170C1300 0x100>, /* DMA0 VC3 */
				<0x170C1400 0x100>; /* DMA0 Common */
			mux_reg = <0x17020414 0x4>; /* DMA0 input mux */
		};
	};

	lic_lut_origin: lic-lut-origin {
		#define LIC_MODE_DYNAMIC	(0)
		#define LIC_MODE_STATIC		(1)
		#define LIC_PATH_OTF		(0)
		#define LIC_PATH_DMA		(1)
		/*
		 * When DYNAMIC mode is selected, param means enable limitation for DMA path.
		 * Example:
		 * @ mode = <LIC_MODE_DYNAMIC>;
		 * @ param0 = <LIC_PATH_OTF>;
		 * @ param1 = <LIC_PATH_DMA>;
		 * @ param2 = <LIC_PATH_OTF>;
		 *
		 * When STATIC mode is selected, param means buffer size for each context.
		 * Example:
		 * @ mode = <LIC_MODE_STAIC>;
		 * @ param0 = <3584>;
		 * @ param1 = <3583>;
		 * @ param2 = <1>;
		 *
		 * The lic_scen0 is not abailable. If the index of LUT is "0", the selection is skipped.
		 */
		lic_scen0 { /* Reserved */
			mode = <0>;
			param0 = <0>;
			param1 = <0>;
			param2 = <0>;
		};
	};

	sensor_paf_pdp_0: sensor-paf-pdp@17090000 {
		/* PDP CORE0 */
		compatible = "samsung,sensor-paf-pdp";
		reg = <0x0 0x17090000 0x10000>, /* PDP CORE0 */
			<0x0 0x17090000 0x10000>, /* PDP CORE0: For common regiser */
			<0x0 0x17020408 0x4>, /* PDP input mux(CSIS_PDP_SC_CON0) in SYSREG */
			<0x0 0x17020448 0x4>; /* CSIS_PDP_SC_PDP_IN_EN in SYSREG */
		reg-names = "core", "common", "mux", "en";
		interrupts = <0 INTREQ__PDP_TOP0 IRQ_TYPE_LEVEL_HIGH>,
			<0 INTREQ__PDP_TOP1 IRQ_TYPE_LEVEL_HIGH>;
		mux =  <0 1 2 3 4 5>; /* <csi0 csi1 csi2 csi3 csi4 csi5> */
		en =  <0 1 2 3 4 5>; /* bit postion: <csi0 csi1 csi2 csi3 csi4 csi5> */
		leader; /* have RDMA & create video node */
		lic_lut = <&lic_lut_origin>;
		clocks = <&clock GATE_CSIS_PDP_TOP>;
		clock-names = "aclk";

	};

	sensor_paf_pdp_1: sensor-paf-pdp@170A0000 {
		/* PDP CORE1 */
		compatible = "samsung,sensor-paf-pdp";
		reg = <0x0 0x170A0000 0x10000>, /* PDP CORE1 */
			<0x0 0x17090000 0x10000>, /* PDP CORE0: For common regiser */
			<0x0 0x1702040C 0x4>, /* PDP input mux(CSIS_PDP_SC_CON1) in SYSREG */
			<0x0 0x17020448 0x4>; /* CSIS_PDP_SC_PDP_IN_EN in SYSREG */
		reg-names = "core", "common", "mux", "en";
		interrupts = <0 INTREQ__PDP_TOP2 IRQ_TYPE_LEVEL_HIGH>,
			<0 INTREQ__PDP_TOP3 IRQ_TYPE_LEVEL_HIGH>;
		mux =  <0 1 2 3 4 5>; /* <csi0 csi1 csi2 csi3 csi4 csi5> */
		en =  <6 7 8 9 10 11>; /* bit postion: <csi0 csi1 csi2 csi3 csi4 csi5> */
		leader; /* have RDMA & create video node */
		lic_lut = <&lic_lut_origin>;
		clocks = <&clock GATE_CSIS_PDP_TOP>;
		clock-names = "aclk";
	};

	sensor_paf_pdp_2: sensor-paf-pdp@170B0000 {
		/* PDP CORE2 */
		compatible = "samsung,sensor-paf-pdp";
		reg = <0x0 0x170B0000 0x10000>, /* PDP CORE2 */
			<0x0 0x17090000 0x10000>, /* PDP CORE0: For common regiser */
			<0x0 0x17020410 0x4>, /* PDP input mux(CSIS_PDP_SC_CON2) in SYSREG */
			<0x0 0x17020448 0x4>; /* CSIS_PDP_SC_PDP_IN_EN in SYSREG */
		reg-names = "core", "common", "mux", "en";
		interrupts = <0 INTREQ__PDP_TOP4 IRQ_TYPE_LEVEL_HIGH>,
			<0 INTREQ__PDP_TOP5 IRQ_TYPE_LEVEL_HIGH>;
		mux =  <0 1 2 3 4 5>; /* <csi0 csi1 csi2 csi3 csi4 csi5> */
		en =  <12 13 14 15 16 17>; /* bit postion: <csi0 csi1 csi2 csi3 csi4 csi5> */
		leader; /* have RDMA & create video node */
		lic_lut = <&lic_lut_origin>;
		clocks = <&clock GATE_CSIS_PDP_TOP>;
		clock-names = "aclk";
	};

	aliases {
		pdp0 = &sensor_paf_pdp_0;
		pdp1 = &sensor_paf_pdp_1;
		pdp2 = &sensor_paf_pdp_2;
	};
};
